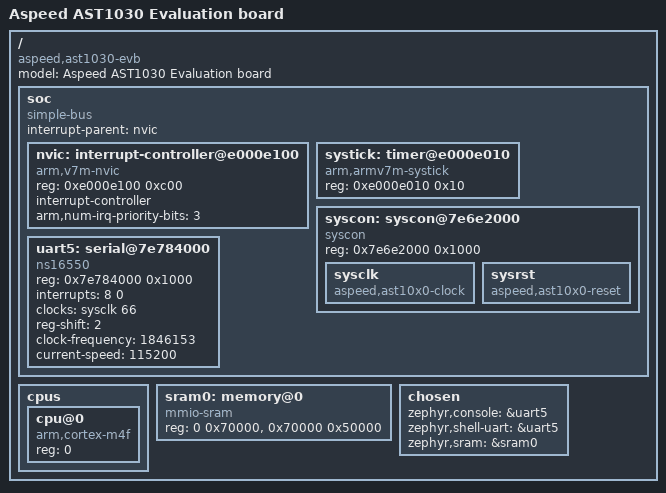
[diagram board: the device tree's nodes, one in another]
/*
 * Copyright (c) 2021 Aspeed Technology Inc.
 *
 * SPDX-License-Identifier: Apache-2.0
 *
 * This file is derived from an intermediate build stage of the Zephr RTOS.
 */

/dts-v1/;

/ {
    #address-cells = <1>;
    #size-cells = <1>;

    soc {
        #address-cells = <1>;
        #size-cells = <1>;
        compatible = "simple-bus";
        interrupt-parent = <&nvic>;
        ranges;

        nvic: interrupt-controller@e000e100 {
            #address-cells = <1>;
            compatible = "arm,v7m-nvic";
            reg = <0xe000e100 0xc00>;
            interrupt-controller;
            #interrupt-cells = <2>;
        };

        systick: timer@e000e010 {
            compatible = "arm,armv7m-systick";
            reg = <0xe000e010 0x10>;
        };
    };
};

/ {
    cpus {
        #address-cells = <1>;
        #size-cells = <0>;

        cpu@0 {
            device_type = "cpu";
            compatible = "arm,cortex-m4f";
            reg = <0>;
        };
    };

    sram0: memory@0 {
        compatible = "mmio-sram";
    };

    soc {
        syscon: syscon@7e6e2000 {
            compatible = "syscon";
            reg = <0x7e6e2000 0x1000>;

            sysclk: sysclk {
                compatible = "aspeed,ast10x0-clock";
                #clock-cells = <1>;
            };

            sysrst: sysrst {
                compatible = "aspeed,ast10x0-reset";
                #reset-cells = <1>;
            };
        };

        uart5: serial@7e784000 {
            compatible = "ns16550";
            reg = <0x7e784000 0x1000>;
            interrupts = <8 0>;
            clocks = <&sysclk 66>;
            status = "disabled";
            reg-shift = <2>;
        };
    };
};

&nvic {
    arm,num-irq-priority-bits = <3>;
};


/ {
    model = "Aspeed AST1030 Evaluation board";
    compatible = "aspeed,ast1030-evb";

    chosen {
        zephyr,console = &uart5;
        zephyr,shell-uart = &uart5;
        zephyr,sram = &sram0;
    };
};

&sram0 {
    reg = <0 0x70000>, <0x70000 0x50000>;
};

&uart5 {
    clock-frequency = <1846153>;
    current-speed = <115200>;
    status = "okay";
};
